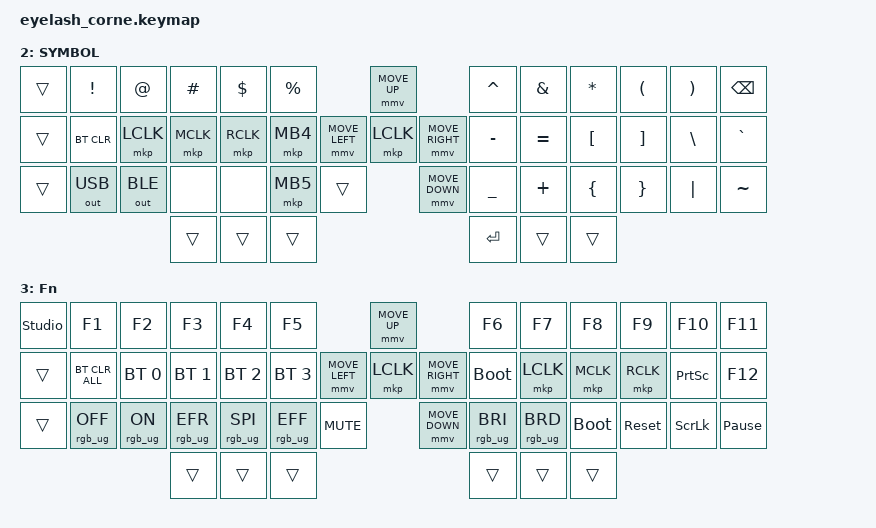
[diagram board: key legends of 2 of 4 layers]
#define ZMK_POINTING_DEFAULT_MOVE_VAL 1200  // 600
#define ZMK_POINTING_DEFAULT_SCRL_VAL 25   // 10

#include <input/processors.dtsi>
#include <zephyr/dt-bindings/input/input-event-codes.h>
#include <behaviors.dtsi>
#include <dt-bindings/zmk/bt.h>
#include <dt-bindings/zmk/keys.h>
#include <dt-bindings/zmk/outputs.h>
#include <dt-bindings/zmk/pointing.h>
#include <dt-bindings/zmk/rgb.h>


// funciones para acceso con hold ant tap
#define HRML(k1,k2,k3,k4) &ht LSHFT k1  &ht LCTRL  k2  &ht LALT  k3  &ht LGUI  k4
#define HRMR(k1,k2,k3,k4) &ht RGUI  k1 &ht RALT k2  &ht RCTRL k3  &ht RSHFT  k4

#define CAGL(k1,k2,k3) &ht LCTRL k1  &ht LALT k2  &ht LGUI  k3
#define CAGR(k1,k2,k3) &ht LGUI  k1  &ht LALT k2  &ht LCTRL  k3

// === Macros para acentos y ñ (macOS U.S.) ===
//1. Configuración de Tap Dance
/ {
    behaviors {
        // Define un comportamiento de Tap Dance para cada vocal y la ñ
        td_a: tap_dance_acute_a {
            compatible = "zmk,behavior-tap-dance";
            #binding-cells = <0>;
            tapping-term-ms = <250>; // Tiempo máximo entre taps
            bindings = <&kp A>, <&a_acute>; // 1 tap: a | 2 taps: á
        };
        // Tap Dance para A/Á (mayúsculas)
        td_MA: tap_dance_acute_MA {
            compatible = "zmk,behavior-tap-dance";
            #binding-cells = <0>;
            tapping-term-ms = <250>;
            bindings = <&kp LS(A)>, <&MA_acute>; // 1 tap: A | 2 taps: Á
        };
        td_e: tap_dance_acute_e {
            compatible = "zmk,behavior-tap-dance";
            #binding-cells = <0>;
            tapping-term-ms = <200>;
            bindings = <&kp E>, <&e_acute>;
        };
        // Tap Dance para E (mayúsculas)
        td_ME: tap_dance_acute_ME {
            compatible = "zmk,behavior-tap-dance";
            #binding-cells = <0>;
            tapping-term-ms = <200>;
            bindings = <&kp LS(E)>, <&ME_acute>;
        };
        td_i: tap_dance_acute_i {
            compatible = "zmk,behavior-tap-dance";
            #binding-cells = <0>;
            tapping-term-ms = <200>;
            bindings = <&kp I>, <&i_acute>;
        };
        // Tap Dance para I (mayúsculas)
        td_MI: tap_dance_acute_MI {
            compatible = "zmk,behavior-tap-dance";
            #binding-cells = <0>;
            tapping-term-ms = <200>;
            bindings = <&kp LS(I)>, <&MI_acute>;
        };
        td_o: tap_dance_acute_o {
            compatible = "zmk,behavior-tap-dance";
            #binding-cells = <0>;
            tapping-term-ms = <200>;
            bindings = <&kp O>, <&o_acute>;
        };
        // Tap Dance para O (mayúsculas)
        td_MO: tap_dance_acute_MO {
            compatible = "zmk,behavior-tap-dance";
            #binding-cells = <0>;
            tapping-term-ms = <200>;
            bindings = <&kp LS(O)>, <&MO_acute>;
        };
        td_u: tap_dance_acute_u {
            compatible = "zmk,behavior-tap-dance";
            #binding-cells = <0>;
            tapping-term-ms = <200>;
            bindings = <&kp U>, <&u_acute>;
        };
        // Tap Dance para U (mayúsculas)
        td_MU: tap_dance_acute_MU {
            compatible = "zmk,behavior-tap-dance";
            #binding-cells = <0>;
            tapping-term-ms = <200>;
            bindings = <&kp LS(U)>, <&MU_acute>;
        };
        td_n: tap_dance_tilde_n {
            compatible = "zmk,behavior-tap-dance";
            #binding-cells = <0>;
            tapping-term-ms = <200>;
            bindings = <&kp N>, <&n_tilde>; // 1 tap: n | 2 taps: ñ
        };
        // Tap Dance para N (mayúsculas)
        td_MN: tap_dance_acute_MN {
            compatible = "zmk,behavior-tap-dance";
            #binding-cells = <0>;
            tapping-term-ms = <200>;
            bindings = <&kp LS(N)>, <&MN_acute>;
        };
    };
};

//2. Define las macros para acentos y ñ
/ {
    macros {
        // Macro para á (Alt + E + A)
        a_acute: a_acute {
            compatible = "zmk,behavior-macro";
            #binding-cells = <0>;
            bindings = <&kp LA(E)>, <&kp A>;
        };
        // Macro para Á (Alt + E + Shift + a)
        MA_acute: MA_acute {
            compatible = "zmk,behavior-macro";
            #binding-cells = <0>;
            bindings = <&kp LA(E)>, <&kp LS(A)>; // LS = Left Shift
        };
        // Macro para é (Alt + E + E)
        e_acute: e_acute {
            compatible = "zmk,behavior-macro";
            #binding-cells = <0>;
            bindings = <&kp LA(E)>, <&kp E>;
        };
        // Macro para E 
        ME_acute: ME_acute {
            compatible = "zmk,behavior-macro";
            #binding-cells = <0>;
            bindings = <&kp LA(E)>, <&kp LS(E)>; // LS = Left Shift
        };
        // Macro para í (Alt + E + I)
        i_acute: i_acute {
            compatible = "zmk,behavior-macro";
            #binding-cells = <0>;
            bindings = <&kp LA(E)>, <&kp I>;
        };
        // Macro para I
        MI_acute: MI_acute {
            compatible = "zmk,behavior-macro";
            #binding-cells = <0>;
            bindings = <&kp LA(E)>, <&kp LS(I)>; // LS = Left Shift
        };
        // Macro para ó (Alt + E + O)
        o_acute: o_acute {
            compatible = "zmk,behavior-macro";
            #binding-cells = <0>;
            bindings = <&kp LA(E)>, <&kp O>;
        };
        // Macro para O
        MO_acute: MO_acute {
            compatible = "zmk,behavior-macro";
            #binding-cells = <0>;
            bindings = <&kp LA(E)>, <&kp LS(O)>; // LS = Left Shift
        };
        // Macro para ú (Alt + E + U)
        u_acute: u_acute {
            compatible = "zmk,behavior-macro";
            #binding-cells = <0>;
            bindings = <&kp LA(E)>, <&kp U>;
        };
        // Macro para U
        MU_acute: MU_acute {
            compatible = "zmk,behavior-macro";
            #binding-cells = <0>;
            bindings = <&kp LA(E)>, <&kp LS(U)>; // LS = Left Shift
        };
        // Macro para ñ (Alt + N + N)
        n_tilde: n_tilde {
            compatible = "zmk,behavior-macro";
            #binding-cells = <0>;
            bindings = <&kp LA(N)>, <&kp N>;
        };
        // Macro para Ñ
        MN_acute: MN_acute {
            compatible = "zmk,behavior-macro";
            #binding-cells = <0>;
            bindings = <&kp LA(N)>, <&kp LS(N)>; // LS = Left Shift
        };
    };
};
//3. Usa mod-morph para alternar entre minúsculas y mayúsculas
/ {
    behaviors {
        // Alterna entre Tap Dance de a/á y A/Á con Shift
        m_a: morph_acute_a {
            compatible = "zmk,behavior-mod-morph";
            #binding-cells = <0>;
            bindings = <&td_a>, <&td_MA>; // Sin Shift: a/á | Con Shift: A/Á
            mods = <(MOD_LSFT|MOD_RSFT)>;
        };
        // Alterna entre Tap Dance con Shift
        m_e: morph_acute_e {
            compatible = "zmk,behavior-mod-morph";
            #binding-cells = <0>;
            bindings = <&td_e>, <&td_ME>; // Sin Shift | Con Shift: 
            mods = <(MOD_LSFT|MOD_RSFT)>;
        };
        // Alterna entre Tap Dance con Shift
        m_i: morph_acute_i {
            compatible = "zmk,behavior-mod-morph";
            #binding-cells = <0>;
            bindings = <&td_i>, <&td_MI>; // Sin Shift | Con Shift: 
            mods = <(MOD_LSFT|MOD_RSFT)>;
        };
        // Alterna entre Tap Dance con Shift
        m_o: morph_acute_o {
            compatible = "zmk,behavior-mod-morph";
            #binding-cells = <0>;
            bindings = <&td_o>, <&td_MO>; // Sin Shift | Con Shift: 
            mods = <(MOD_LSFT|MOD_RSFT)>;
        };
        // Alterna entre Tap Dance con Shift
        m_u: morph_acute_u {
            compatible = "zmk,behavior-mod-morph";
            #binding-cells = <0>;
            bindings = <&td_u>, <&td_MU>; // Sin Shift | Con Shift: 
            mods = <(MOD_LSFT|MOD_RSFT)>;
        };
        // Alterna entre Tap Dance con Shift
        m_n: morph_acute_n {
            compatible = "zmk,behavior-mod-morph";
            #binding-cells = <0>;
            bindings = <&td_n>, <&td_MN>; // Sin Shift | Con Shift: 
            mods = <(MOD_LSFT|MOD_RSFT)>;
        };
    };
};


// === Macros para acentos y ñ (macOS U.S.) ===


/ {
    macros {
        my_appl: my_appl {
            label = "ZM_my_appl";
            compatible = "zmk,behavior-macro";
            #binding-cells = <0>;
            wait-ms = <5>;
            tap-ms = <5>;
            bindings
                = <&macro_tap &kp C &kp S &kp A &kp N &kp H &kp U &kp E  &kp Z &kp A &kp A &kp AT &kp R &kp A &kp L &kp U &kp N &kp T &kp E &kp C &kp H &kp DOT &kp C &kp O &kp M>

                ;
        };
    };
};

/ {
    macros {
        rut_rpy: rut_rpy {
            label = "ZM_rut_rpy";
            compatible = "zmk,behavior-macro";
            #binding-cells = <0>;
            wait-ms = <5>;
            tap-ms = <5>;
            bindings
                = <&macro_tap &kp N8 &kp N3 &kp N3 &kp N8 &kp N2 &kp N7 &kp N0 &kp N0 &kp MINUS &kp N6>

                ;
        };
    };
};

/ {
    macros {
        my_p: my_p {
            label = "ZM_my_p";
            compatible = "zmk,behavior-macro";
            #binding-cells = <0>;
            wait-ms = <5>;
            tap-ms = <5>;
            bindings
                = <&macro_tap  &kp M  &kp A &kp U &kp R &kp N1 &kp N1>

                ;
        };
    };
};

/ {
    macros {
        my_m: my_m {
            label = "ZM_my_m";
            compatible = "zmk,behavior-macro";
            #binding-cells = <0>;
            wait-ms = <5>;
            tap-ms = <5>;
            bindings
                = <&macro_tap  &kp C  &kp R &kp S &kp A &kp L  &kp M &kp A &kp R &kp Z  &kp A &kp AT &kp G &kp M &kp A &kp I &kp L &kp DOT &kp C &kp O &kp M>

                ;
        };
    };
};


#define SYM_SPC  &lt 2 SPACE
//#define LCA_ENT  &mt LC(LALT) ENTER
#define SFT_ENT  &ht RSHFT ENTER
#define SFT_ESC  &ht RSHFT ESC
#define ALT_ESC  &ht LALT ESC
#define SFT_BSPC &ht RSHFT BSPC
#define GUI_BSPC  &ht RGUI BSPC
//#define GUI_TAB  &ht RGUI LG(TAB)
#define GUI_ENT  &ht RGUI ENTER
#define GUI_SPC  &ht RGUI SPACE
#define CTL_TAB  &ht LCTRL TAB
#define CTL_ESC  &ht LCTRL ESC
#define CTL_ACUTE &ht LCTRL ACUTE
#define CTL_SPC  &ht RCTRL SPACE
#define SFT_Z  &ht LSHFT Z
#define SFT_A  &ht LSHFT  &m_a 
#define PRE  &kp C_PREV
#define VDN  &kp C_VOL_DN
#define VUP  &kp C_VOL_UP
#define NXT  &kp C_NEXT
#define PLP  &kp C_PP

#define LFT  &kp LEFT
#define DWN  &kp DOWN
#define UPT  &kp UP
#define RHT  &kp RIGHT

//HRML(C_PREV   , C_VOL_DN , C_VOL_UP ,  C_NEXT  )
#define NUM_TAB  &lt 1 TAB
#define NUM_SPC  &lt 1 SPACE
#define FUN_SPC  &lt 3 SPACE

&mmv_input_listener { input-processors = <&zip_xy_scaler 2 1>; };

&msc_input_listener { input-processors = <&zip_scroll_scaler 2 1>; };

&msc {
    acceleration-exponent = <1>;      // 0
    time-to-max-speed-ms = <100>;       // 300
    delay-ms = <0>;                   // 0
};

&mmv {
    time-to-max-speed-ms = <500>;
    acceleration-exponent = <1>;
    trigger-period-ms = <16>;
};

/ {
    behaviors {
        td0: td0 {
            compatible = "zmk,behavior-tap-dance";
            display-name = "Shift/Caps Lock Tap Dance";
            #binding-cells = <0>;
            bindings = <&kp LEFT_SHIFT>, <&kp CAPS>;
        };
        ht: hold_tap {
            label = "hold_tap";
            compatible = "zmk,behavior-hold-tap";
            #binding-cells = <2>;
            flavor = "tap-preferred";
            tapping-term-ms = <220>;
            quick-tap-ms = <150>;
            global-quick-tap;
            bindings = <&kp>, <&kp>;
        };
    };

    rgb_encoder: rgb_encoder {
        compatible = "zmk,behavior-sensor-rotate";
        #sensor-binding-cells = <0>;
        bindings = <&rgb_ug RGB_BRI>, <&rgb_ug RGB_BRD>;
    };

    scroll_encoder: scroll_encoder {
        compatible = "zmk,behavior-sensor-rotate";
        #sensor-binding-cells = <0>;
        bindings = <&msc SCRL_DOWN>, <&msc SCRL_UP>;

        tap-ms = <100>;
    };

    keymap {
        compatible = "zmk,keymap";

        default_layer {
            display-name = "QWERTY";
            bindings = <
&kp TAB    &kp Q  &kp W  &m_e     &kp R  &kp T                               &kp UP                &kp Y        &m_u    &m_i      &m_o    &kp P     &kp SQT
&td0       &m_a CAGL( S    , D   ,   F )  &kp G                     &kp LEFT  &kp ENTER  &kp RIGHT  &kp H  CAGR(   J  ,     K     ,  L )   &kp SEMI  &kp BSPC 
&kp LCTRL  &kp Z  &kp X  &kp C    &kp V  &kp B        &kp SPACE              &kp DOWN              &m_n        &kp M  &kp COMMA  &kp DOT  &kp FSLH   SFT_ENT
                         SFT_ESC  NUM_SPC  GUI_ENT                                               FUN_SPC  SYM_SPC  ALT_ESC
            >;

             sensor-bindings = <&inc_dec_kp C_VOLUME_UP C_VOLUME_DOWN>;

           
        };

        lower_layer {
            display-name = "NUMBER";
            bindings = <
&trans  &kp N1           &kp N2          &kp N3        &kp N4        &kp N5                                         &mmv MOVE_UP                     &kp N6           &kp N7           &kp N8           &kp N9      &kp N0    &trans
&trans  &kp LEFT     CAGL(DOWN            ,UP        ,RIGHT  )        &kp HOME                       &mmv MOVE_LEFT  &mkp LCLK    &mmv MOVE_RIGHT  &kp END    CAGR(  N4               ,N5             ,N6 )       &kp PG_UP  &trans
&trans   PRE              VDN             VUP           NXT           PLP         &kp C_MUTE                      &mmv MOVE_DOWN                   &my_p          &kp N1            &kp N2          &kp N3        &kp PG_DN  &trans
                                         &trans        &trans        &trans                                                                  &kp INS          &kp DEL          &trans
            >;


            sensor-bindings = <&scroll_encoder>;
        };

        raise_layer {
            display-name = "SYMBOL";
            bindings = <
&trans  &kp EXCL      &kp AT        &kp HASH   &kp DLLR   &kp PRCNT                            &mmv MOVE_UP                     &kp CARET  &kp AMPS   &kp ASTRK  &kp LPAR  &kp RPAR  &kp BSPC
&trans  &bt BT_CLR    &mkp LCLK     &mkp MCLK  &mkp RCLK  &mkp MB4             &mmv MOVE_LEFT  &mkp LCLK       &mmv MOVE_RIGHT  &kp MINUS  &kp EQUAL  &kp LBKT   &kp RBKT  &kp BSLH  &kp GRAVE
&trans  &out OUT_USB  &out OUT_BLE  &none      &none      &mkp MB5   &trans                    &mmv MOVE_DOWN                   &kp UNDER  &kp PLUS   &kp LBRC   &kp RBRC  &kp PIPE  &kp TILDE
                                    &trans     &trans     &trans                                                             &kp RET    &trans     &trans
            >;

            sensor-bindings = <&scroll_encoder>;
        };

        layer_3 {
            display-name = "Fn";
            bindings = <
&studio_unlock  &kp F1      &kp F2     &kp F3       &kp F4     &kp F5                                  &mmv MOVE_UP                     &kp F6       &kp F7     &kp F8       &kp F9      &kp F10          &kp F11
&trans &bt BT_CLR_ALL   &bt BT_SEL 0    &bt BT_SEL 1  &bt BT_SEL 2  &bt BT_SEL 3                 &mmv MOVE_LEFT  &mkp LCLK       &mmv MOVE_RIGHT  &bootloader  &mkp LCLK  &mkp MCLK    &mkp RCLK   &kp PRINTSCREEN  &kp F12
&trans   &rgb_ug RGB_OFF  &rgb_ug RGB_ON &rgb_ug RGB_EFR  &rgb_ug RGB_SPI  &rgb_ug RGB_EFF  &kp C_MUTE                    &mmv MOVE_DOWN         &rgb_ug RGB_BRI  &rgb_ug RGB_BRD    &bootloader  &sys_reset  &kp SCROLLLOCK   &kp PAUSE_BREAK
                                       &trans       &trans     &trans                                                                   &trans       &trans     &trans
            >;


  
            sensor-bindings = <&scroll_encoder>;
        };
    };
};
